AUTOSAR XML (schema 00051)
package /swc
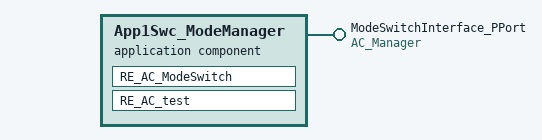
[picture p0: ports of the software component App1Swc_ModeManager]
  application sw component type App1Swc_ModeManager
    provide port ModeSwitchInterface_PPort: provided-interface=AC_Manager, mode-switch-sender-com-spec{enhanced-mode-api=false, mode-group=AC_Manager_MDGroup, mode-switched-ack=timeout=10, queue-length=10}
    behavior IB_AC_Controller
      runnable RE_AC_ModeSwitch
        mode switch point RE_AC_ModeSwitchPoint: return-value-provision=NO-RETURN-VALUE-PROVIDED, mode-group=ModeSwitchInterface_PPort.AC_Manager_MDGroup
      runnable RE_AC_test
      swc mode switch event EV_AC_ModeSwitch: start-on-event=RE_AC_ModeSwitch
  application sw component type App2Swc_ModeUser
    require port ModeSwitchInterface_RPort: required-interface=AC_Manager, mode-switch-receiver-com-spec{enhanced-mode-api=false, mode-group=AC_Manager_MDGroup, supports-asynchronous-mode-switch=false}
    behavior IB_AC_Mode_Display
      13 x runnable:
        RE_Mode0_Entry
        RE_Mode0_Exit
        RE_Mode0_Transition
        RE_Mode1_Entry
        RE_Mode1_Exit
        RE_Mode1_Transition
        RE_Mode2_Entry
        RE_Mode2_Exit
        RE_Mode2_Transition
        RE_{0..2}
        RE_3: mode-access-point=ModeSwitchInterface_RPort.AC_Manager_MDGroup
      13 x swc mode switch event:
        EV_0: start-on-event=RE_0, disabled-mode=INITMODE
        EV_1: start-on-event=RE_1, disabled-mode=CODE
        EV_2: start-on-event=RE_2, disabled-mode=HEAT
        EV_3: start-on-event=RE_3
        EV_Mode0_Entry: start-on-event=RE_Mode0_Entry, activation=ON-ENTRY, mode=AC_Manager_MDGroup.ModeSwitchInterface_RPort.INITMODE
        EV_Mode0_Exit: start-on-event=RE_Mode0_Exit, activation=ON-EXIT, mode=AC_Manager_MDGroup.ModeSwitchInterface_RPort.INITMODE
        EV_Mode0_Transition: start-on-event=RE_Mode0_Transition, activation=ON-TRANSITION, mode=AC_Manager_MDGroup.ModeSwitchInterface_RPort.INITMODE
        EV_Mode1_Entry: start-on-event=RE_Mode1_Entry, activation=ON-ENTRY, mode=AC_Manager_MDGroup.ModeSwitchInterface_RPort.CODE
        EV_Mode1_Exit: start-on-event=RE_Mode1_Exit, activation=ON-EXIT, mode=AC_Manager_MDGroup.ModeSwitchInterface_RPort.CODE
        EV_Mode1_Transition: start-on-event=RE_Mode1_Transition, activation=ON-TRANSITION, mode=AC_Manager_MDGroup.ModeSwitchInterface_RPort.CODE
        EV_Mode2_Entry: start-on-event=RE_Mode2_Entry, activation=ON-ENTRY, mode=AC_Manager_MDGroup.ModeSwitchInterface_RPort.HEAT
        EV_Mode2_Exit: start-on-event=RE_Mode2_Exit, activation=ON-EXIT, mode=AC_Manager_MDGroup.ModeSwitchInterface_RPort.HEAT
        EV_Mode2_Transition: start-on-event=RE_Mode2_Transition, activation=ON-TRANSITION, mode=AC_Manager_MDGroup.ModeSwitchInterface_RPort.HEAT
  composition sw component type CompositionSwc
    component Component_ModeManager: type=App1Swc_ModeManager
    component Component_ModeUser: type=App2Swc_ModeUser
    connect Component_ModeManager.ModeSwitchInterface_PPort -> Component_ModeUser.ModeSwitchInterface_RPort
package /swc/AC_MDGroup
  mode declaration group AC_MDGroup: category=ALPHABETIC_ORDER, initial-mode=INITMODE, mode-manager-error-behavior=error-reaction-policy=DEFAULT-MODE, mode-user-error-behavior=error-reaction-policy=DEFAULT-MODE
    mode INITMODE
    mode CODE
    mode HEAT
package /swc/ModeSwitchInterface
  mode switch interface AC_Manager
    mode group AC_Manager_MDGroup: type=AC_MDGroup
